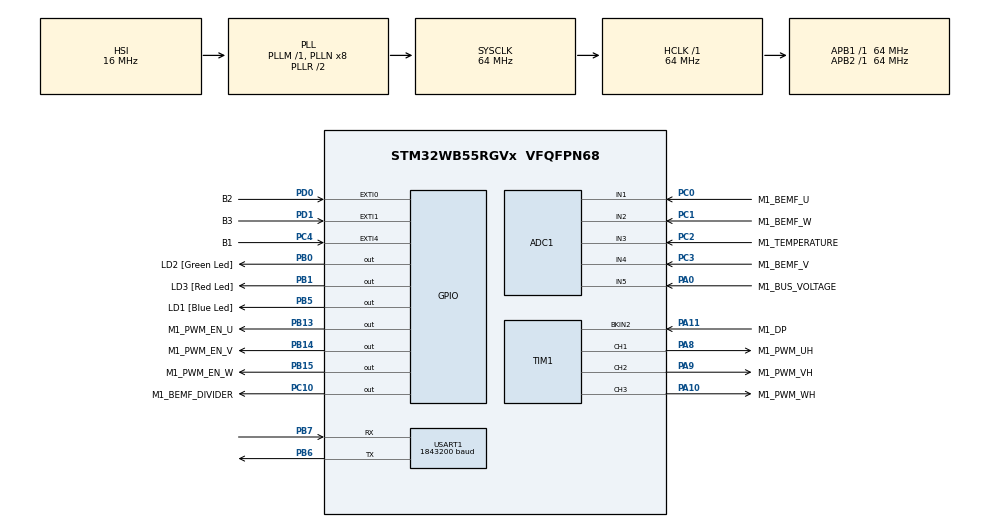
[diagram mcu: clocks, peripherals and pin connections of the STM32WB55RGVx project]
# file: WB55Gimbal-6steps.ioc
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ADC1.Channel-0\#ChannelRegularConversion=ADC_CHANNEL_1
ADC1.DataAlign=ADC_DATAALIGN_LEFT
ADC1.EnableInjectedConversion=ENABLE
ADC1.ExternalTrigInjecConv=ADC_EXTERNALTRIGINJEC_T1_TRGO
ADC1.ExternalTrigInjecConvEdge=ADC_EXTERNALTRIGINJECCONV_EDGE_FALLING
ADC1.InjMonitoredBy-1\#ChannelInjectedConversion=__NULL
ADC1.InjNumberOfConversion=1
ADC1.InjectedChannel-1\#ChannelInjectedConversion=ADC_CHANNEL_1
ADC1.InjectedOffsetNumber-1\#ChannelInjectedConversion=ADC_OFFSET_NONE
ADC1.InjectedRank-1\#ChannelInjectedConversion=1
ADC1.InjectedSamplingTime-1\#ChannelInjectedConversion=ADC_SAMPLETIME_2CYCLES_5
ADC1.NbrOfConversionFlag=1
ADC1.OffsetNumber-0\#ChannelRegularConversion=ADC_OFFSET_NONE
ADC1.Rank-0\#ChannelRegularConversion=1
ADC1.Rank1_Channel=ADC_CHANNEL_1
ADC1.SamplingTime-0\#ChannelRegularConversion=ADC_SAMPLETIME_2CYCLES_5
ADC1.master=1
Dma.Request0=USART1_RX
Dma.Request1=USART1_TX
Dma.USART1_RX.0.Direction=DMA_PERIPH_TO_MEMORY
Dma.USART1_RX.0.EventEnable=DISABLE
Dma.USART1_RX.0.Instance=DMA1_Channel1
Dma.USART1_RX.0.MemDataAlignment=DMA_MDATAALIGN_BYTE
Dma.USART1_RX.0.MemInc=DMA_MINC_ENABLE
Dma.USART1_RX.0.Mode=DMA_NORMAL
Dma.USART1_RX.0.PeriphDataAlignment=DMA_PDATAALIGN_BYTE
Dma.USART1_RX.0.PeriphInc=DMA_PINC_DISABLE
Dma.USART1_RX.0.Polarity=HAL_DMAMUX_REQ_GEN_RISING
Dma.USART1_RX.0.Priority=DMA_PRIORITY_LOW
Dma.USART1_RX.0.RequestNumber=1
Dma.USART1_RX.0.SignalID=NONE
Dma.USART1_RX.0.SyncEnable=DISABLE
Dma.USART1_RX.0.SyncPolarity=HAL_DMAMUX_SYNC_NO_EVENT
Dma.USART1_RX.0.SyncRequestNumber=1
Dma.USART1_RX.0.SyncSignalID=NONE
Dma.USART1_TX.1.Direction=DMA_MEMORY_TO_PERIPH
Dma.USART1_TX.1.EventEnable=DISABLE
Dma.USART1_TX.1.Instance=DMA1_Channel2
Dma.USART1_TX.1.MemDataAlignment=DMA_MDATAALIGN_BYTE
Dma.USART1_TX.1.MemInc=DMA_MINC_ENABLE
Dma.USART1_TX.1.Mode=DMA_NORMAL
Dma.USART1_TX.1.PeriphDataAlignment=DMA_PDATAALIGN_BYTE
Dma.USART1_TX.1.PeriphInc=DMA_PINC_DISABLE
Dma.USART1_TX.1.Polarity=HAL_DMAMUX_REQ_GEN_RISING
Dma.USART1_TX.1.Priority=DMA_PRIORITY_LOW
Dma.USART1_TX.1.RequestNumber=1
Dma.USART1_TX.1.SignalID=NONE
Dma.USART1_TX.1.SyncEnable=DISABLE
Dma.USART1_TX.1.SyncPolarity=HAL_DMAMUX_SYNC_NO_EVENT
Dma.USART1_TX.1.SyncRequestNumber=1
Dma.USART1_TX.1.SyncSignalID=NONE
Mcu.Family=STM32WB
Mcu.Name=STM32WB55RGVx
Mcu.Package=VFQFPN68
NVIC.ADC1_IRQn=true\:1\:0\:true\:false\:true\:true\:true\:true
NVIC.DMA1_Channel1_IRQn=true\:3\:0\:true\:false\:true\:false\:true\:true
NVIC.EXTI0_IRQn=true\:14\:0\:true\:false\:true\:true\:true\:true
NVIC.EXTI1_IRQn=true\:14\:0\:true\:false\:true\:true\:true\:true
NVIC.EXTI4_IRQn=true\:14\:0\:true\:false\:true\:true\:true\:true
NVIC.PriorityGroup=NVIC_PRIORITYGROUP_4
NVIC.TIM1_BRK_IRQn=true\:1\:0\:true\:false\:true\:true\:true\:true
NVIC.TIM1_UP_TIM16_IRQn=true\:1\:0\:true\:false\:true\:true\:true\:true
NVIC.TIM2_IRQn=true\:2\:0\:true\:false\:true\:true\:true\:true
NVIC.USART1_IRQn=true\:2\:0\:true\:false\:true\:true\:true\:true
OSC_IN.Signal=RCC_OSC_IN
OSC_OUT.Signal=RCC_OSC_OUT
PA0.GPIO_Label=M1_BUS_VOLTAGE
PA0.Signal=ADCx_IN5
PA10.GPIO_Label=M1_PWM_WH
PA10.GPIO_PuPd=GPIO_PULLDOWN
PA10.GPIO_Speed=GPIO_SPEED_FREQ_HIGH
PA10.Signal=S_TIM1_CH3
PA11.GPIO_Label=M1_DP
PA11.GPIO_PuPd=GPIO_PULLUP
PA11.Mode=Activate-Break-Input-2
PA11.Signal=TIM1_BKIN2
PA13.Mode=Trace_Asynchronous_SW
PA13.Signal=SYS_JTMS-SWDIO
PA14.Mode=Trace_Asynchronous_SW
PA14.Signal=SYS_JTCK-SWCLK
PA8.GPIO_Label=M1_PWM_UH
PA8.GPIO_PuPd=GPIO_PULLDOWN
PA8.GPIO_Speed=GPIO_SPEED_FREQ_HIGH
PA8.Signal=S_TIM1_CH1
PA9.GPIO_Label=M1_PWM_VH
PA9.GPIO_PuPd=GPIO_PULLDOWN
PA9.GPIO_Speed=GPIO_SPEED_FREQ_HIGH
PA9.Signal=S_TIM1_CH2
PB0.GPIO_Label=LD2 [Green Led]
PB0.Signal=GPIO_Output
PB1.GPIO_Label=LD3 [Red Led]
PB1.Signal=GPIO_Output
PB13.GPIO_Label=M1_PWM_EN_U
PB13.GPIO_PuPd=GPIO_PULLDOWN
PB13.GPIO_Speed=GPIO_SPEED_FREQ_HIGH
PB13.Signal=GPIO_Output
PB14.GPIO_Label=M1_PWM_EN_V
PB14.GPIO_PuPd=GPIO_PULLDOWN
PB14.GPIO_Speed=GPIO_SPEED_FREQ_HIGH
PB14.Signal=GPIO_Output
PB15.GPIO_Label=M1_PWM_EN_W
PB15.Signal=GPIO_Output
PB3.Mode=Trace_Asynchronous_SW
PB3.Signal=SYS_JTDO-SWO
PB5.GPIO_Label=LD1 [Blue Led]
PB5.Signal=GPIO_Output
PB6.GPIO_PuPd=GPIO_PULLUP
PB6.Mode=Asynchronous
PB6.Signal=USART1_TX
PB7.GPIO_PuPd=GPIO_PULLUP
PB7.Mode=Asynchronous
PB7.Signal=USART1_RX
PC0.GPIO_Label=M1_BEMF_U
PC0.Signal=ADCx_IN1
PC1.GPIO_Label=M1_BEMF_W
PC1.Signal=ADCx_IN2
PC10.GPIO_Label=M1_BEMF_DIVIDER
PC10.GPIO_PuPd=GPIO_PULLDOWN
PC10.Signal=GPIO_Output
PC2.GPIO_Label=M1_TEMPERATURE
PC2.Signal=ADCx_IN3
PC3.GPIO_Label=M1_BEMF_V
PC3.Signal=ADCx_IN4
PC4.GPIO_Label=B1
PC4.GPIO_PuPd=GPIO_PULLUP
PC4.Signal=GPXTI4
PD0.GPIO_Label=B2
PD0.GPIO_PuPd=GPIO_PULLUP
PD0.Signal=GPXTI0
PD1.GPIO_Label=B3
PD1.GPIO_PuPd=GPIO_PULLUP
PD1.Signal=GPXTI1
ProjectManager.HeapSize=0x1000
ProjectManager.StackSize=0x1000
ProjectManager.TargetToolchain=EWARM V9.20
RCC.ADCCLockSelection=RCC_ADCCLKSOURCE_PLL
RCC.ADCFreq_Value=16000000
RCC.AHB2CLKDivider=RCC_SYSCLK_DIV2
RCC.AHBFreq_Value=64000000
RCC.APB1Freq_Value=64000000
RCC.APB1TimFreq_Value=64000000
RCC.APB2Freq_Value=64000000
RCC.APB2TimFreq_Value=64000000
RCC.APB3Freq_Value=16000000
RCC.Cortex2_Div=SYSTICK_CLKSOURCE_HCLK_DIV8
RCC.CortexFreq_Value=64000000
RCC.HCLKFreq_Value=64000000
RCC.HSE_VALUE=32000000
RCC.HSI48_VALUE=48000000
RCC.HSI_VALUE=16000000
RCC.LSE_VALUE=32.77
RCC.PLLP=RCC_PLLP_DIV8
RCC.PLLSAI1N=6
RCC.PLLSAI1R=RCC_PLLR_DIV6
RCC.PLLSourceVirtual=RCC_PLLSOURCE_HSI
RCC.SMPSCLockSelectionVirtual=RCC_SMPSCLKSOURCE_HSI
RCC.SMPSCLockSelectionVirtualVirtual=RCC_SMPSCLKSOURCE_HSI
RCC.SMPSDivider=1
RCC.SYSCLKFreq_VALUE=64000000
RCC.SYSCLKSource=RCC_SYSCLKSOURCE_PLLCLK
RCC.USBFreq_Value=48000000
RCC.VCOOutputFreq_Value=128000000
SH.ADCx_IN1.0=ADC1_IN1,IN1-Single-Ended
SH.ADCx_IN2.0=ADC1_IN2,IN2-Single-Ended
SH.ADCx_IN3.0=ADC1_IN3,IN3-Single-Ended
SH.ADCx_IN4.0=ADC1_IN4,IN4-Single-Ended
SH.ADCx_IN5.0=ADC1_IN5,IN5-Single-Ended
SH.S_TIM1_CH1.0=TIM1_CH1,PWM Generation1 CH1
SH.S_TIM1_CH2.0=TIM1_CH2,PWM Generation2 CH2
SH.S_TIM1_CH3.0=TIM1_CH3,PWM Generation3 CH3
TIM1.Break2Filter=3
TIM1.Channel-PWM\ Generation1\ CH1=TIM_CHANNEL_1
TIM1.Channel-PWM\ Generation2\ CH2=TIM_CHANNEL_2
TIM1.Channel-PWM\ Generation3\ CH3=TIM_CHANNEL_3
TIM1.Channel-PWM\ Generation4\ No\ Output=TIM_CHANNEL_4
TIM1.Period=(PWM_PERIOD_CYCLES)
TIM1.RepetitionCounter=(REP_COUNTER)
TIM1.SourceBRK2DigInputPolarity=TIM_BREAKINPUTSOURCE_POLARITY_LOW
TIM1.TIM_MasterOutputTrigger=TIM_TRGO_OC4REF
TIM1.TIM_MasterSlaveMode=TIM_MASTERSLAVEMODE_ENABLE
TIM2.Period=LF_TIMER_ARR
TIM2.Prescaler=LF_TIMER_PSC
TIM2.TIM_MasterOutputTrigger=TIM_TRGO_ENABLE
TIM2.TIM_MasterSlaveMode=TIM_MASTERSLAVEMODE_ENABLE
USART1.BaudRate=1843200
USART1.VirtualMode-Asynchronous=VM_ASYNC
USART1.WordLength=WORDLENGTH_8B
VP_MEMORYMAP_VS_MEMORYMAP.Mode=CurAppReg
VP_TIM1_VS_ClockSourceINT.Mode=Internal
VP_TIM1_VS_no_output4.Mode=PWM Generation4 No Output
VP_TIM2_VS_ClockSourceINT.Mode=Internal
board=NUCLEO-WB55RG

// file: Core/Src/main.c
/* USER CODE BEGIN Header */
/**
  ******************************************************************************
  * @file           : main.c
  * @brief          : Main program body
  ******************************************************************************
  * @attention
  *
  * Copyright (c) 2024 STMicroelectronics.
  * All rights reserved.
  *
  * This software is licensed under terms that can be found in the LICENSE file
  * in the root directory of this software component.
  * If no LICENSE file comes with this software, it is provided AS-IS.
  *
  ******************************************************************************
  */
/* USER CODE END Header */
#include "main.h"

/* USER CODE BEGIN Includes */
#include "mc_tasks.h"
/* USER CODE END Includes */

ADC_HandleTypeDef hadc1;

TIM_HandleTypeDef htim1;
TIM_HandleTypeDef htim2;

UART_HandleTypeDef huart1;
DMA_HandleTypeDef hdma_usart1_rx;
DMA_HandleTypeDef hdma_usart1_tx;

void SystemClock_Config(void);
void PeriphCommonClock_Config(void);
static void MX_GPIO_Init(void);
static void MX_DMA_Init(void);
static void MX_ADC1_Init(void);
static void MX_TIM1_Init(void);
static void MX_TIM2_Init(void);
static void MX_USART1_UART_Init(void);

int main(void)
{

  /* USER CODE BEGIN 1 */
  /**
   * The OPTVERR flag is wrongly set at power on
   * It shall be cleared before using any HAL_FLASH_xxx() api
   */
  __HAL_FLASH_CLEAR_FLAG( FLASH_FLAG_OPTVERR );
  /* USER CODE END 1 */

  /* MCU Configuration--------------------------------------------------------*/

  /* Reset of all peripherals, Initializes the Flash interface and the Systick. */
  HAL_Init();

  /* Configure the system clock */
  SystemClock_Config();

/* Configure the peripherals common clocks */
  PeriphCommonClock_Config();

  /* Initialize all configured peripherals */
  MX_GPIO_Init();
  MX_DMA_Init();
  MX_ADC1_Init();
  MX_TIM1_Init();
  MX_TIM2_Init();
  MX_USART1_UART_Init();
  /* USER CODE BEGIN 2 */
  MX_MotorControl_Init();
  /* USER CODE END 2 */

  /* Infinite loop */
  while (1)
  {

  }
}

void SystemClock_Config(void)
{
  RCC_OscInitTypeDef RCC_OscInitStruct = {0};
  RCC_ClkInitTypeDef RCC_ClkInitStruct = {0};

  /** Configure the main internal regulator output voltage
  */
  __HAL_PWR_VOLTAGESCALING_CONFIG(PWR_REGULATOR_VOLTAGE_SCALE1);

  /** Initializes the RCC Oscillators according to the specified parameters
  * in the RCC_OscInitTypeDef structure.
  */
  RCC_OscInitStruct.OscillatorType = RCC_OSCILLATORTYPE_HSI;
  RCC_OscInitStruct.HSIState = RCC_HSI_ON;
  RCC_OscInitStruct.HSICalibrationValue = RCC_HSICALIBRATION_DEFAULT;
  RCC_OscInitStruct.PLL.PLLState = RCC_PLL_ON;
  RCC_OscInitStruct.PLL.PLLSource = RCC_PLLSOURCE_HSI;
  RCC_OscInitStruct.PLL.PLLM = RCC_PLLM_DIV1;
  RCC_OscInitStruct.PLL.PLLN = 8;
  RCC_OscInitStruct.PLL.PLLP = RCC_PLLP_DIV8;
  RCC_OscInitStruct.PLL.PLLR = RCC_PLLR_DIV2;
  RCC_OscInitStruct.PLL.PLLQ = RCC_PLLQ_DIV2;
  if (HAL_RCC_OscConfig(&RCC_OscInitStruct) != HAL_OK)
  {
    Error_Handler();
  }

  /** Configure the SYSCLKSource, HCLK, PCLK1 and PCLK2 clocks dividers
  */
  RCC_ClkInitStruct.ClockType = RCC_CLOCKTYPE_HCLK4|RCC_CLOCKTYPE_HCLK2
                              |RCC_CLOCKTYPE_HCLK|RCC_CLOCKTYPE_SYSCLK
                              |RCC_CLOCKTYPE_PCLK1|RCC_CLOCKTYPE_PCLK2;
  RCC_ClkInitStruct.SYSCLKSource = RCC_SYSCLKSOURCE_PLLCLK;
  RCC_ClkInitStruct.AHBCLKDivider = RCC_SYSCLK_DIV1;
  RCC_ClkInitStruct.APB1CLKDivider = RCC_HCLK_DIV1;
  RCC_ClkInitStruct.APB2CLKDivider = RCC_HCLK_DIV1;
  RCC_ClkInitStruct.AHBCLK2Divider = RCC_SYSCLK_DIV2;
  RCC_ClkInitStruct.AHBCLK4Divider = RCC_SYSCLK_DIV1;

  if (HAL_RCC_ClockConfig(&RCC_ClkInitStruct, FLASH_LATENCY_3) != HAL_OK)
  {
    Error_Handler();
  }
}

void PeriphCommonClock_Config(void)
{
  RCC_PeriphCLKInitTypeDef PeriphClkInitStruct = {0};

  /** Initializes the peripherals clock
  */
  PeriphClkInitStruct.PeriphClockSelection = RCC_PERIPHCLK_SMPS;
  PeriphClkInitStruct.SmpsClockSelection = RCC_SMPSCLKSOURCE_HSI;
  PeriphClkInitStruct.SmpsDivSelection = RCC_SMPSCLKDIV_RANGE0;

  if (HAL_RCCEx_PeriphCLKConfig(&PeriphClkInitStruct) != HAL_OK)
  {
    Error_Handler();
  }
}

static void MX_ADC1_Init(void)
{

  ADC_ChannelConfTypeDef sConfig = {0};
  ADC_InjectionConfTypeDef sConfigInjected = {0};

  /** Common config
  */
  hadc1.Instance = ADC1;
  hadc1.Init.ClockPrescaler = ADC_CLOCK_ASYNC_DIV1;
  hadc1.Init.Resolution = ADC_RESOLUTION_12B;
  hadc1.Init.DataAlign = ADC_DATAALIGN_LEFT;
  hadc1.Init.ScanConvMode = ADC_SCAN_DISABLE;
  hadc1.Init.EOCSelection = ADC_EOC_SINGLE_CONV;
  hadc1.Init.LowPowerAutoWait = DISABLE;
  hadc1.Init.ContinuousConvMode = DISABLE;
  hadc1.Init.NbrOfConversion = 1;
  hadc1.Init.DiscontinuousConvMode = DISABLE;
  hadc1.Init.ExternalTrigConv = ADC_SOFTWARE_START;
  hadc1.Init.ExternalTrigConvEdge = ADC_EXTERNALTRIGCONVEDGE_NONE;
  hadc1.Init.DMAContinuousRequests = DISABLE;
  hadc1.Init.Overrun = ADC_OVR_DATA_PRESERVED;
  hadc1.Init.OversamplingMode = DISABLE;
  if (HAL_ADC_Init(&hadc1) != HAL_OK)
  {
    Error_Handler();
  }

  /** Disable Injected Queue
  */
  HAL_ADCEx_DisableInjectedQueue(&hadc1);

  /** Configure Regular Channel
  */
  sConfig.Channel = ADC_CHANNEL_1;
  sConfig.Rank = ADC_REGULAR_RANK_1;
  sConfig.SamplingTime = ADC_SAMPLETIME_2CYCLES_5;
  sConfig.SingleDiff = ADC_SINGLE_ENDED;
  sConfig.OffsetNumber = ADC_OFFSET_NONE;
  sConfig.Offset = 0;
  if (HAL_ADC_ConfigChannel(&hadc1, &sConfig) != HAL_OK)
  {
    Error_Handler();
  }

  /** Configure Injected Channel
  */
  sConfigInjected.InjectedChannel = ADC_CHANNEL_1;
  sConfigInjected.InjectedRank = ADC_INJECTED_RANK_1;
  sConfigInjected.InjectedSamplingTime = ADC_SAMPLETIME_2CYCLES_5;
  sConfigInjected.InjectedSingleDiff = ADC_SINGLE_ENDED;
  sConfigInjected.InjectedOffsetNumber = ADC_OFFSET_NONE;
  sConfigInjected.InjectedOffset = 0;
  sConfigInjected.InjectedNbrOfConversion = 1;
  sConfigInjected.InjectedDiscontinuousConvMode = DISABLE;
  sConfigInjected.AutoInjectedConv = DISABLE;
  sConfigInjected.QueueInjectedContext = DISABLE;
  sConfigInjected.ExternalTrigInjecConv = ADC_EXTERNALTRIGINJEC_T1_TRGO;
  sConfigInjected.ExternalTrigInjecConvEdge = ADC_EXTERNALTRIGINJECCONV_EDGE_FALLING;
  sConfigInjected.InjecOversamplingMode = DISABLE;
  if (HAL_ADCEx_InjectedConfigChannel(&hadc1, &sConfigInjected) != HAL_OK)
  {
    Error_Handler();
  }

}

static void MX_TIM1_Init(void)
{

  TIM_ClockConfigTypeDef sClockSourceConfig = {0};
  TIM_MasterConfigTypeDef sMasterConfig = {0};
  TIMEx_BreakInputConfigTypeDef sBreakInputConfig = {0};
  TIM_OC_InitTypeDef sConfigOC = {0};
  TIM_BreakDeadTimeConfigTypeDef sBreakDeadTimeConfig = {0};

  htim1.Instance = TIM1;
  htim1.Init.Prescaler = 0;
  htim1.Init.CounterMode = TIM_COUNTERMODE_UP;
  htim1.Init.Period = (PWM_PERIOD_CYCLES);
  htim1.Init.ClockDivision = TIM_CLOCKDIVISION_DIV1;
  htim1.Init.RepetitionCounter = (REP_COUNTER);
  htim1.Init.AutoReloadPreload = TIM_AUTORELOAD_PRELOAD_DISABLE;
  if (HAL_TIM_Base_Init(&htim1) != HAL_OK)
  {
    Error_Handler();
  }
  sClockSourceConfig.ClockSource = TIM_CLOCKSOURCE_INTERNAL;
  if (HAL_TIM_ConfigClockSource(&htim1, &sClockSourceConfig) != HAL_OK)
  {
    Error_Handler();
  }
  if (HAL_TIM_PWM_Init(&htim1) != HAL_OK)
  {
    Error_Handler();
  }
  sMasterConfig.MasterOutputTrigger = TIM_TRGO_OC4REF;
  sMasterConfig.MasterOutputTrigger2 = TIM_TRGO2_RESET;
  sMasterConfig.MasterSlaveMode = TIM_MASTERSLAVEMODE_ENABLE;
  if (HAL_TIMEx_MasterConfigSynchronization(&htim1, &sMasterConfig) != HAL_OK)
  {
    Error_Handler();
  }
  sBreakInputConfig.Source = TIM_BREAKINPUTSOURCE_BKIN;
  sBreakInputConfig.Enable = TIM_BREAKINPUTSOURCE_ENABLE;
  sBreakInputConfig.Polarity = TIM_BREAKINPUTSOURCE_POLARITY_LOW;
  if (HAL_TIMEx_ConfigBreakInput(&htim1, TIM_BREAKINPUT_BRK2, &sBreakInputConfig) != HAL_OK)
  {
    Error_Handler();
  }
  sConfigOC.OCMode = TIM_OCMODE_PWM1;
  sConfigOC.Pulse = 0;
  sConfigOC.OCPolarity = TIM_OCPOLARITY_HIGH;
  sConfigOC.OCNPolarity = TIM_OCNPOLARITY_HIGH;
  sConfigOC.OCFastMode = TIM_OCFAST_DISABLE;
  sConfigOC.OCIdleState = TIM_OCIDLESTATE_RESET;
  sConfigOC.OCNIdleState = TIM_OCNIDLESTATE_RESET;
  if (HAL_TIM_PWM_ConfigChannel(&htim1, &sConfigOC, TIM_CHANNEL_1) != HAL_OK)
  {
    Error_Handler();
  }
  if (HAL_TIM_PWM_ConfigChannel(&htim1, &sConfigOC, TIM_CHANNEL_2) != HAL_OK)
  {
    Error_Handler();
  }
  if (HAL_TIM_PWM_ConfigChannel(&htim1, &sConfigOC, TIM_CHANNEL_3) != HAL_OK)
  {
    Error_Handler();
  }
  if (HAL_TIM_PWM_ConfigChannel(&htim1, &sConfigOC, TIM_CHANNEL_4) != HAL_OK)
  {
    Error_Handler();
  }
  sBreakDeadTimeConfig.OffStateRunMode = TIM_OSSR_ENABLE;
  sBreakDeadTimeConfig.OffStateIDLEMode = TIM_OSSI_ENABLE;
  sBreakDeadTimeConfig.LockLevel = TIM_LOCKLEVEL_OFF;
  sBreakDeadTimeConfig.DeadTime = 0;
  sBreakDeadTimeConfig.BreakState = TIM_BREAK_DISABLE;
  sBreakDeadTimeConfig.BreakPolarity = TIM_BREAKPOLARITY_HIGH;
  sBreakDeadTimeConfig.BreakFilter = 0;
  sBreakDeadTimeConfig.BreakAFMode = TIM_BREAK_AFMODE_INPUT;
  sBreakDeadTimeConfig.Break2State = TIM_BREAK2_ENABLE;
  sBreakDeadTimeConfig.Break2Polarity = TIM_BREAK2POLARITY_HIGH;
  sBreakDeadTimeConfig.Break2Filter = 3;
  sBreakDeadTimeConfig.Break2AFMode = TIM_BREAK_AFMODE_INPUT;
  sBreakDeadTimeConfig.AutomaticOutput = TIM_AUTOMATICOUTPUT_DISABLE;
  if (HAL_TIMEx_ConfigBreakDeadTime(&htim1, &sBreakDeadTimeConfig) != HAL_OK)
  {
    Error_Handler();
  }
  HAL_TIM_MspPostInit(&htim1);

}

static void MX_TIM2_Init(void)
{

  TIM_ClockConfigTypeDef sClockSourceConfig = {0};
  TIM_MasterConfigTypeDef sMasterConfig = {0};

  htim2.Instance = TIM2;
  htim2.Init.Prescaler = LF_TIMER_PSC;
  htim2.Init.CounterMode = TIM_COUNTERMODE_UP;
  htim2.Init.Period = LF_TIMER_ARR;
  htim2.Init.ClockDivision = TIM_CLOCKDIVISION_DIV1;
  htim2.Init.AutoReloadPreload = TIM_AUTORELOAD_PRELOAD_DISABLE;
  if (HAL_TIM_Base_Init(&htim2) != HAL_OK)
  {
    Error_Handler();
  }
  sClockSourceConfig.ClockSource = TIM_CLOCKSOURCE_INTERNAL;
  if (HAL_TIM_ConfigClockSource(&htim2, &sClockSourceConfig) != HAL_OK)
  {
    Error_Handler();
  }
  sMasterConfig.MasterOutputTrigger = TIM_TRGO_ENABLE;
  sMasterConfig.MasterSlaveMode = TIM_MASTERSLAVEMODE_ENABLE;
  if (HAL_TIMEx_MasterConfigSynchronization(&htim2, &sMasterConfig) != HAL_OK)
  {
    Error_Handler();
  }

}

static void MX_USART1_UART_Init(void)
{

  huart1.Instance = USART1;
  huart1.Init.BaudRate = 1843200;
  huart1.Init.WordLength = UART_WORDLENGTH_8B;
  huart1.Init.StopBits = UART_STOPBITS_1;
  huart1.Init.Parity = UART_PARITY_NONE;
  huart1.Init.Mode = UART_MODE_TX_RX;
  huart1.Init.HwFlowCtl = UART_HWCONTROL_NONE;
  huart1.Init.OverSampling = UART_OVERSAMPLING_16;
  huart1.Init.OneBitSampling = UART_ONE_BIT_SAMPLE_DISABLE;
  huart1.Init.ClockPrescaler = UART_PRESCALER_DIV1;
  huart1.AdvancedInit.AdvFeatureInit = UART_ADVFEATURE_NO_INIT;
  if (HAL_UART_Init(&huart1) != HAL_OK)
  {
    Error_Handler();
  }
  if (HAL_UARTEx_SetTxFifoThreshold(&huart1, UART_TXFIFO_THRESHOLD_1_8) != HAL_OK)
  {
    Error_Handler();
  }
  if (HAL_UARTEx_SetRxFifoThreshold(&huart1, UART_RXFIFO_THRESHOLD_1_8) != HAL_OK)
  {
    Error_Handler();
  }
  if (HAL_UARTEx_DisableFifoMode(&huart1) != HAL_OK)
  {
    Error_Handler();
  }

}

static void MX_DMA_Init(void)
{

  /* DMA controller clock enable */
  __HAL_RCC_DMAMUX1_CLK_ENABLE();
  __HAL_RCC_DMA1_CLK_ENABLE();

  /* DMA interrupt init */
  /* DMA1_Channel1_IRQn interrupt configuration */
  HAL_NVIC_SetPriority(DMA1_Channel1_IRQn, 3, 0);
  HAL_NVIC_EnableIRQ(DMA1_Channel1_IRQn);

}

static void MX_GPIO_Init(void)
{
  GPIO_InitTypeDef GPIO_InitStruct = {0};

  /* GPIO Ports Clock Enable */
  __HAL_RCC_GPIOC_CLK_ENABLE();
  __HAL_RCC_GPIOA_CLK_ENABLE();
  __HAL_RCC_GPIOB_CLK_ENABLE();
  __HAL_RCC_GPIOD_CLK_ENABLE();

  /*Configure GPIO pin Output Level */
  HAL_GPIO_WritePin(GPIOB, LD2_Pin|LD3_Pin|M1_PWM_EN_U_Pin|M1_PWM_EN_V_Pin
                          |M1_PWM_EN_W_Pin|LD1_Pin, GPIO_PIN_RESET);

  /*Configure GPIO pin Output Level */
  HAL_GPIO_WritePin(M1_BEMF_DIVIDER_GPIO_Port, M1_BEMF_DIVIDER_Pin, GPIO_PIN_RESET);

  /*Configure GPIO pin : B1_Pin */
  GPIO_InitStruct.Pin = B1_Pin;
  GPIO_InitStruct.Mode = GPIO_MODE_IT_RISING;
  GPIO_InitStruct.Pull = GPIO_PULLUP;
  HAL_GPIO_Init(B1_GPIO_Port, &GPIO_InitStruct);

  /*Configure GPIO pins : LD2_Pin LD3_Pin M1_PWM_EN_W_Pin LD1_Pin */
  GPIO_InitStruct.Pin = LD2_Pin|LD3_Pin|M1_PWM_EN_W_Pin|LD1_Pin;
  GPIO_InitStruct.Mode = GPIO_MODE_OUTPUT_PP;
  GPIO_InitStruct.Pull = GPIO_NOPULL;
  GPIO_InitStruct.Speed = GPIO_SPEED_FREQ_LOW;
  HAL_GPIO_Init(GPIOB, &GPIO_InitStruct);

  /*Configure GPIO pins : M1_PWM_EN_U_Pin M1_PWM_EN_V_Pin */
  GPIO_InitStruct.Pin = M1_PWM_EN_U_Pin|M1_PWM_EN_V_Pin;
  GPIO_InitStruct.Mode = GPIO_MODE_OUTPUT_PP;
  GPIO_InitStruct.Pull = GPIO_PULLDOWN;
  GPIO_InitStruct.Speed = GPIO_SPEED_FREQ_HIGH;
  HAL_GPIO_Init(GPIOB, &GPIO_InitStruct);

  /*Configure GPIO pin : M1_BEMF_DIVIDER_Pin */
  GPIO_InitStruct.Pin = M1_BEMF_DIVIDER_Pin;
  GPIO_InitStruct.Mode = GPIO_MODE_OUTPUT_PP;
  GPIO_InitStruct.Pull = GPIO_PULLDOWN;
  GPIO_InitStruct.Speed = GPIO_SPEED_FREQ_LOW;
  HAL_GPIO_Init(M1_BEMF_DIVIDER_GPIO_Port, &GPIO_InitStruct);

  /*Configure GPIO pins : B2_Pin B3_Pin */
  GPIO_InitStruct.Pin = B2_Pin|B3_Pin;
  GPIO_InitStruct.Mode = GPIO_MODE_IT_RISING;
  GPIO_InitStruct.Pull = GPIO_PULLUP;
  HAL_GPIO_Init(GPIOD, &GPIO_InitStruct);

  /* EXTI interrupt init*/
  HAL_NVIC_SetPriority(EXTI0_IRQn, 14, 0);
  HAL_NVIC_EnableIRQ(EXTI0_IRQn);

  HAL_NVIC_SetPriority(EXTI1_IRQn, 14, 0);
  HAL_NVIC_EnableIRQ(EXTI1_IRQn);

  HAL_NVIC_SetPriority(EXTI4_IRQn, 14, 0);
  HAL_NVIC_EnableIRQ(EXTI4_IRQn);

}

/* USER CODE BEGIN 4 */
/**
  * @brief  EXTI line detection callback.
  * @param GPIO_Pin Specifies the port pin connected to corresponding EXTI line.
  * @retval None
  */
void HAL_GPIO_EXTI_Callback(uint16_t GPIO_Pin)
{
  switch(GPIO_Pin)
  {
    case B1_Pin:
      (void) UI_HandleStartStopButton_cb();
      break;

    default:
      break;
  }
}
/* USER CODE END 4 */

void Error_Handler(void)
{
  __disable_irq();
  while (1)
  {
  }
}
